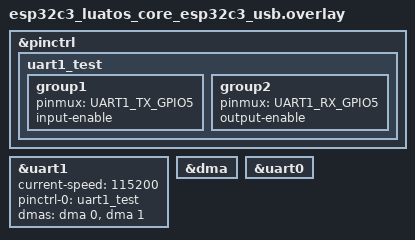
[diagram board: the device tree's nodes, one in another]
/*
 * Copyright (c) 2023 Espressif Systems (Shanghai) Co., Ltd.
 * Copyright (c) 2023 YuLong Yao<feilongphone@gmail.com>
 *
 * SPDX-License-Identifier: Apache-2.0
 */

&pinctrl {
	uart1_test: uart1_test {
		group1 {
			pinmux = <UART1_TX_GPIO5>;
			input-enable;
		};
		group2 {
			pinmux = <UART1_RX_GPIO5>;
			output-enable;
		};
	};
};

dut: &uart1 {
	status = "okay";
	current-speed = <115200>;
	pinctrl-0 = <&uart1_test>;
	pinctrl-names = "default";
	dmas = <&dma 0>, <&dma 1>;
	dma-names = "rx", "tx";
};

&dma {
	status = "okay";
};

&uart0 {
	status = "okay";
};
